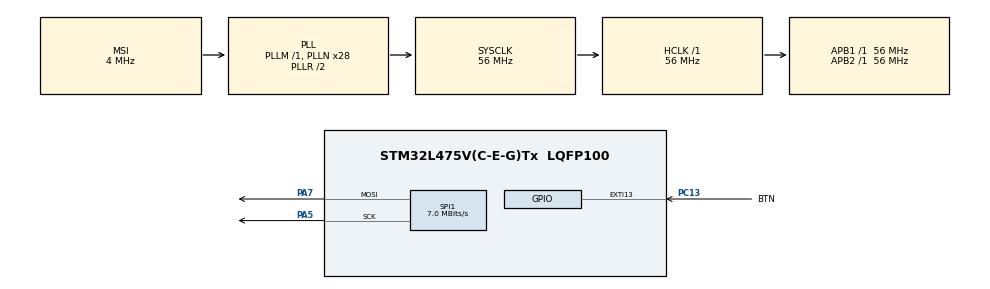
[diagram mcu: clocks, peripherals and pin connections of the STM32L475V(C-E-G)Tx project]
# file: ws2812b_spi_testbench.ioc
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Mcu.Family=STM32L4
RCC.MSI_VALUE=4000000
Dma.SPI1_TX.0.MemInc=DMA_MINC_ENABLE
Dma.SPI1_TX.0.PeriphInc=DMA_PINC_DISABLE
RCC.CortexFreq_Value=56000000
PA7.Mode=TX_Only_Simplex_Unidirect_Master
SPI1.VirtualType=VM_MASTER
PC13.Signal=GPXTI13
PC13.GPIO_Label=BTN
RCC.SYSCLKSource=RCC_SYSCLKSOURCE_PLLCLK
ProjectManager.StackSize=0x400
NVIC.DMA1_Channel3_IRQn=true\:0\:0\:false\:false\:true\:false\:true
ProjectManager.TargetToolchain=STM32CubeIDE
SPI1.Direction=SPI_DIRECTION_2LINES
Dma.SPI1_TX.0.PeriphDataAlignment=DMA_PDATAALIGN_BYTE
RCC.HCLKFreq_Value=56000000
Dma.SPI1_TX.0.Direction=DMA_MEMORY_TO_PERIPH
RCC.APB2TimFreq_Value=56000000
SPI1.CalculateBaudRate=7.0 MBits/s
RCC.USBFreq_Value=48000000
RCC.LSE_VALUE=32768
RCC.AHBFreq_Value=56000000
NVIC.EXTI15_10_IRQn=true\:0\:0\:false\:false\:true\:true\:true
PA5.Signal=SPI1_SCK
RCC.HSE_VALUE=8000000
board=B-L475E-IOT01A1
RCC.VCOOutputFreq_Value=112000000
NVIC.SPI1_IRQn=true\:1\:0\:true\:false\:true\:true\:true
RCC.APB2Freq_Value=56000000
SPI1.Mode=SPI_MODE_MASTER
RCC.ADCFreq_Value=48000000
SPI1.DataSize=SPI_DATASIZE_8BIT
Dma.SPI1_TX.0.Instance=DMA1_Channel3
SPI1.FirstBit=SPI_FIRSTBIT_LSB
Mcu.Name=STM32L475V(C-E-G)Tx
Dma.SPI1_TX.0.Mode=DMA_NORMAL
RCC.SYSCLKFreq_VALUE=56000000
Mcu.Package=LQFP100
ProjectManager.HeapSize=0x200
Dma.SPI1_TX.0.Priority=DMA_PRIORITY_LOW
Dma.SPI1_TX.0.MemDataAlignment=DMA_MDATAALIGN_BYTE
RCC.HSI_VALUE=16000000
NVIC.PriorityGroup=NVIC_PRIORITYGROUP_4
RCC.PLLN=28
RCC.APB1TimFreq_Value=56000000
RCC.APB1Freq_Value=56000000
Dma.Request0=SPI1_TX
SPI1.BaudRatePrescaler=SPI_BAUDRATEPRESCALER_8
RCC.PLLSAI1N=24
PA5.Mode=TX_Only_Simplex_Unidirect_Master
PA7.Signal=SPI1_MOSI

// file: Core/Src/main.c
/* USER CODE BEGIN Header */
/**
  ******************************************************************************
  * @file           : main.c
  * @brief          : Main program body
  ******************************************************************************
  * @attention
  *
  * <h2><center>&copy; Copyright (c) 2021 STMicroelectronics.
  * All rights reserved.</center></h2>
  *
  * This software component is licensed by ST under BSD 3-Clause license,
  * the "License"; You may not use this file except in compliance with the
  * License. You may obtain a copy of the License at:
  *                        opensource.org/licenses/BSD-3-Clause
  *
  ******************************************************************************
  */
/* USER CODE END Header */
#include "main.h"

/* USER CODE BEGIN Includes */
#include "ws2812b.h"
#include <string.h>

/* USER CODE END Includes */

SPI_HandleTypeDef hspi1;
DMA_HandleTypeDef hdma_spi1_tx;

/* USER CODE BEGIN PV */
volatile uint8_t btn_flag;
/* USER CODE END PV */

void SystemClock_Config(void);
static void MX_GPIO_Init(void);
static void MX_DMA_Init(void);
static void MX_SPI1_Init(void);

int main(void)
{

  /* MCU Configuration--------------------------------------------------------*/

  /* Reset of all peripherals, Initializes the Flash interface and the Systick. */
  HAL_Init();

  /* USER CODE BEGIN Init */
  btn_flag = 0;
  /* USER CODE END Init */

  /* Configure the system clock */
  SystemClock_Config();

  /* Initialize all configured peripherals */
  MX_GPIO_Init();
  MX_DMA_Init();
  MX_SPI1_Init();
  /* USER CODE BEGIN 2 */

  uint8_t d[4] = {0};
  HAL_SPI_Transmit(&hspi1, d, 4, 100); // Send a 0 to make sure the SPI port starts at 0

  ws2812b_led_t leds[3];
  // LED 1 RED
  leds[0].red = 0x00;
  leds[0].green = 0xff;
  leds[0].blue = 0x00;

  // LED 2 GREEN
  leds[1].red = 0xff;
  leds[1].green = 0x00;
  leds[1].blue = 0x00;

  // LED 3 BLUE
  leds[2].red = 0x00;
  leds[2].green = 0x00;
  leds[2].blue = 0xff;

  ws2812b_handle_t hws2812b;
  hws2812b.config.packing = WS2812B_PACKING_SINGLE;
  hws2812b.config.pulse_len_1 = WS2812B_PULSE_LEN_6b;
  hws2812b.config.pulse_len_0 = WS2812B_PULSE_LEN_3b;
  hws2812b.config.first_bit_0 = WS2812B_FIRST_BIT_0_ENABLED;
  hws2812b.config.prefix_len = 1;
  hws2812b.config.suffix_len = 4;
  hws2812b.config.spi_bit_order = WS2812B_LSB_FIRST;

  hws2812b.led_count = 3;
  hws2812b.leds = leds;

  if(ws2812b_init(&hws2812b)){
	  while(1){}
  }

  uint8_t dma_buf[WS2812B_REQUIRED_BUFFER_LEN(3,WS2812B_PACKING_SINGLE,1,4)];

  // Test if iteration returns same as fill_buf, and correctly reports finished.
  ws2812b_fill_buffer(&hws2812b, dma_buf);
  for(int i = 0; i < WS2812B_REQUIRED_BUFFER_LEN(3,WS2812B_PACKING_SINGLE,1,4); i++){
	  uint8_t should = dma_buf[i];
	  uint8_t is = ws2812b_iter_next(&hws2812b);
	  if(is != should){
		  while(1){;}
	  }
	  if(ws2812b_iter_is_finished(&hws2812b) && i != WS2812B_REQUIRED_BUFFER_LEN(3,WS2812B_PACKING_SINGLE,1,4)-1){
		  while(1){;}
	  }
  }

  if(!ws2812b_iter_is_finished(&hws2812b)){
	  while(1){;}
  }

  /* USER CODE END 2 */

  /* Infinite loop */
  /* USER CODE BEGIN WHILE */
  while (1)
  { /*
	while(!btn_flag){
		;
	}
	btn_flag = 0;
	*/

	ws2812b_fill_buffer(&hws2812b, dma_buf);

	HAL_SPI_Transmit_DMA(&hspi1, dma_buf, WS2812B_REQUIRED_BUFFER_LEN(3,WS2812B_PACKING_SINGLE,1,4));

	HAL_Delay(10);

    /* USER CODE END WHILE */

  }
}

void SystemClock_Config(void)
{
  RCC_OscInitTypeDef RCC_OscInitStruct = {0};
  RCC_ClkInitTypeDef RCC_ClkInitStruct = {0};

  /** Initializes the RCC Oscillators according to the specified parameters
  * in the RCC_OscInitTypeDef structure.
  */
  RCC_OscInitStruct.OscillatorType = RCC_OSCILLATORTYPE_MSI;
  RCC_OscInitStruct.MSIState = RCC_MSI_ON;
  RCC_OscInitStruct.MSICalibrationValue = 0;
  RCC_OscInitStruct.MSIClockRange = RCC_MSIRANGE_6;
  RCC_OscInitStruct.PLL.PLLState = RCC_PLL_ON;
  RCC_OscInitStruct.PLL.PLLSource = RCC_PLLSOURCE_MSI;
  RCC_OscInitStruct.PLL.PLLM = 1;
  RCC_OscInitStruct.PLL.PLLN = 28;
  RCC_OscInitStruct.PLL.PLLP = RCC_PLLP_DIV7;
  RCC_OscInitStruct.PLL.PLLQ = RCC_PLLQ_DIV2;
  RCC_OscInitStruct.PLL.PLLR = RCC_PLLR_DIV2;
  if (HAL_RCC_OscConfig(&RCC_OscInitStruct) != HAL_OK)
  {
    Error_Handler();
  }
  /** Initializes the CPU, AHB and APB buses clocks
  */
  RCC_ClkInitStruct.ClockType = RCC_CLOCKTYPE_HCLK|RCC_CLOCKTYPE_SYSCLK
                              |RCC_CLOCKTYPE_PCLK1|RCC_CLOCKTYPE_PCLK2;
  RCC_ClkInitStruct.SYSCLKSource = RCC_SYSCLKSOURCE_PLLCLK;
  RCC_ClkInitStruct.AHBCLKDivider = RCC_SYSCLK_DIV1;
  RCC_ClkInitStruct.APB1CLKDivider = RCC_HCLK_DIV1;
  RCC_ClkInitStruct.APB2CLKDivider = RCC_HCLK_DIV1;

  if (HAL_RCC_ClockConfig(&RCC_ClkInitStruct, FLASH_LATENCY_3) != HAL_OK)
  {
    Error_Handler();
  }
  /** Configure the main internal regulator output voltage
  */
  if (HAL_PWREx_ControlVoltageScaling(PWR_REGULATOR_VOLTAGE_SCALE1) != HAL_OK)
  {
    Error_Handler();
  }
}

static void MX_SPI1_Init(void)
{

  /* SPI1 parameter configuration*/
  hspi1.Instance = SPI1;
  hspi1.Init.Mode = SPI_MODE_MASTER;
  hspi1.Init.Direction = SPI_DIRECTION_2LINES;
  hspi1.Init.DataSize = SPI_DATASIZE_8BIT;
  hspi1.Init.CLKPolarity = SPI_POLARITY_LOW;
  hspi1.Init.CLKPhase = SPI_PHASE_1EDGE;
  hspi1.Init.NSS = SPI_NSS_SOFT;
  hspi1.Init.BaudRatePrescaler = SPI_BAUDRATEPRESCALER_8;
  hspi1.Init.FirstBit = SPI_FIRSTBIT_LSB;
  hspi1.Init.TIMode = SPI_TIMODE_DISABLE;
  hspi1.Init.CRCCalculation = SPI_CRCCALCULATION_DISABLE;
  hspi1.Init.CRCPolynomial = 7;
  hspi1.Init.CRCLength = SPI_CRC_LENGTH_DATASIZE;
  hspi1.Init.NSSPMode = SPI_NSS_PULSE_ENABLE;
  if (HAL_SPI_Init(&hspi1) != HAL_OK)
  {
    Error_Handler();
  }

}

static void MX_DMA_Init(void)
{

  /* DMA controller clock enable */
  __HAL_RCC_DMA1_CLK_ENABLE();

  /* DMA interrupt init */
  /* DMA1_Channel3_IRQn interrupt configuration */
  HAL_NVIC_SetPriority(DMA1_Channel3_IRQn, 0, 0);
  HAL_NVIC_EnableIRQ(DMA1_Channel3_IRQn);

}

static void MX_GPIO_Init(void)
{
  GPIO_InitTypeDef GPIO_InitStruct = {0};

  /* GPIO Ports Clock Enable */
  __HAL_RCC_GPIOC_CLK_ENABLE();
  __HAL_RCC_GPIOA_CLK_ENABLE();

  /*Configure GPIO pin : BTN_Pin */
  GPIO_InitStruct.Pin = BTN_Pin;
  GPIO_InitStruct.Mode = GPIO_MODE_IT_RISING;
  GPIO_InitStruct.Pull = GPIO_NOPULL;
  HAL_GPIO_Init(BTN_GPIO_Port, &GPIO_InitStruct);

  /* EXTI interrupt init*/
  HAL_NVIC_SetPriority(EXTI15_10_IRQn, 0, 0);
  HAL_NVIC_EnableIRQ(EXTI15_10_IRQn);

}

/* USER CODE BEGIN 4 */

void HAL_GPIO_EXTI_Callback(uint16_t GPIO_Pin){
	if(GPIO_Pin == BTN_Pin){
		btn_flag = 1;
	}
}

/* USER CODE END 4 */

void Error_Handler(void)
{
  __disable_irq();
  while (1)
  {
  }
}

/************************ (C) COPYRIGHT STMicroelectronics *****END OF FILE****/
